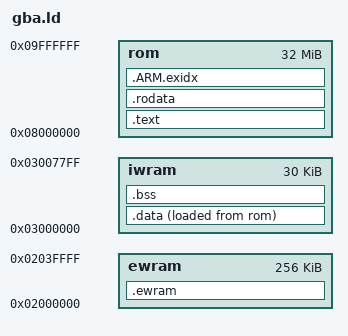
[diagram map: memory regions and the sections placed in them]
OUTPUT_ARCH(arm)
ENTRY(_start)

MEMORY {
    rom   : ORIGIN = 0x08000000, LENGTH = 32M
    iwram : ORIGIN = 0x03000000, LENGTH = 30K
    ewram : ORIGIN = 0x02000000, LENGTH = 256K
}

SECTIONS {
    .text : {
        KEEP(*(.crt0))
        *(.text .text.*)
        *(.glue_7 .glue_7t .vfp11_veneer .v4_bx)
        . = ALIGN(4);
    } > rom
    .rodata : {
        *(.rodata .rodata.*)
        . = ALIGN(4);
    } > rom
    .ARM.exidx : { *(.ARM.exidx*) } > rom

    __data_lma = LOADADDR(.data);
    .data : {
        __data_start = .;
        *(.iwram .iwram.*)
        *(.data .data.*)
        . = ALIGN(4);
        __data_end = .;
    } > iwram AT > rom

    .bss (NOLOAD) : {
        __bss_start = .;
        *(.bss .bss.*)
        *(COMMON)
        . = ALIGN(4);
        __bss_end = .;
    } > iwram

    .ewram (NOLOAD) : {
        __ewram_start = .;
        *(.ewram .ewram.*)
        . = ALIGN(4);
        __ewram_end = .;
    } > ewram
}
